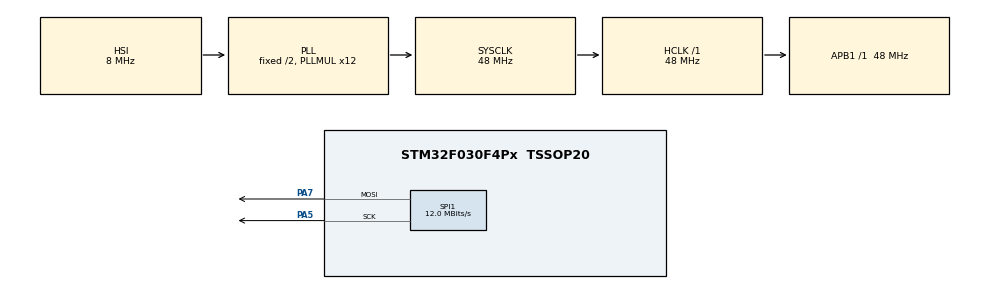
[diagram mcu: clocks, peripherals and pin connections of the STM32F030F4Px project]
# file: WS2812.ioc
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Mcu.Family=STM32F0
Mcu.Name=STM32F030F4Px
Mcu.Package=TSSOP20
NVIC.TIM17_IRQn=true\:0\:0\:false\:false\:true\:true\:true\:true
PA13.Mode=Serial_Wire
PA13.Signal=SYS_SWDIO
PA14.Mode=Serial_Wire
PA14.Signal=SYS_SWCLK
PA5.GPIO_PuPd=GPIO_PULLDOWN
PA5.Mode=TX_Only_Simplex_Unidirect_Master
PA5.Signal=SPI1_SCK
PA7.GPIO_PuPd=GPIO_PULLDOWN
PA7.Mode=TX_Only_Simplex_Unidirect_Master
PA7.Signal=SPI1_MOSI
PF0-OSC_IN.Mode=HSE-External-Oscillator
PF0-OSC_IN.Signal=RCC_OSC_IN
PF1-OSC_OUT.Mode=HSE-External-Oscillator
PF1-OSC_OUT.Signal=RCC_OSC_OUT
ProjectManager.HeapSize=0x200
ProjectManager.StackSize=0x400
ProjectManager.TargetToolchain=STM32CubeIDE
RCC.AHBFreq_Value=48000000
RCC.APB1Freq_Value=48000000
RCC.APB1TimFreq_Value=48000000
RCC.HCLKFreq_Value=48000000
RCC.PLLMUL=RCC_PLL_MUL12
RCC.SYSCLKFreq_VALUE=48000000
RCC.SYSCLKSource=RCC_SYSCLKSOURCE_PLLCLK
SPI1.BaudRatePrescaler=SPI_BAUDRATEPRESCALER_4
SPI1.CalculateBaudRate=12.0 MBits/s
SPI1.DataSize=SPI_DATASIZE_15BIT
SPI1.Direction=SPI_DIRECTION_2LINES
SPI1.Mode=SPI_MODE_MASTER
SPI1.NSSPMode=SPI_NSS_PULSE_DISABLE
SPI1.VirtualType=VM_MASTER
TIM17.AutoReloadPreload=TIM_AUTORELOAD_PRELOAD_ENABLE
TIM17.Prescaler=47999
TIM17.RepetitionCounter=10
VP_TIM17_VS_ClockSourceINT.Mode=Enable_Timer
board=custom

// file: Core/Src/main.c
/* USER CODE BEGIN Header */
/**
  ******************************************************************************
  * @file           : main.c
  * @brief          : Main program body
  ******************************************************************************
  * @attention
  *
  * Copyright (c) 2022 STMicroelectronics.
  * All rights reserved.
  *
  * This software is licensed under terms that can be found in the LICENSE file
  * in the root directory of this software component.
  * If no LICENSE file comes with this software, it is provided AS-IS.
  *
  ******************************************************************************
  */
/* USER CODE END Header */
#include "main.h"

/* USER CODE BEGIN Includes */
#include "stdlib.h"
/* USER CODE END Includes */

/* USER CODE BEGIN PD */
//#define HIGH_CODE (0x7FC0) /*111111111000000*/
//#define LOW_CODE (0x7C00)  /*111110000000000*/
#define HIGH_CODE (0x01FF) /*111111111000000*/
#define LOW_CODE (0x001F)  /*111110000000000*/
/* USER CODE END PD */

SPI_HandleTypeDef hspi1;

TIM_HandleTypeDef htim17;

/* USER CODE BEGIN PV */
uint16_t u16ValueLed[2] =
{
 LOW_CODE,
 HIGH_CODE,
};

uint32_t u32Delay = 1000;
uint32_t u32Colors[5] =
{
 0x0,
 0xFFD000,
 0xFFD000,
 0x00FF00,
 0x0000FF,
};

uint32_t u32ColorsMax[5] =
{
 0x0,
 0xFFD000,
 0xFFD000,
 0x00FF00,
 0x0000FF,
};

/* USER CODE END PV */

void SystemClock_Config(void);
static void MX_GPIO_Init(void);
static void MX_SPI1_Init(void);
static void MX_TIM17_Init(void);

/* USER CODE BEGIN 0 */

void WritePixel(uint8_t Red, uint8_t Green, uint8_t Blue);
void WritePixelColor(uint32_t Color);

void WritePixel(uint8_t Red, uint8_t Green, uint8_t Blue)
{
    uint8_t u8Temp;

    for(int i=0; i<8; i++)
    {
        u8Temp = Green & 0x80;
        Green <<= 1;
        u8Temp >>=7;
        SPI1->DR = u16ValueLed[u8Temp];
        while((SPI1->SR & SPI_SR_FTLVL) == SPI_SR_FTLVL);
    }

    for(int i=0; i<8; i++)
    {
        u8Temp = Red & 0x80;
        Red <<= 1;
        u8Temp >>=7;
        SPI1->DR = u16ValueLed[u8Temp];
        while((SPI1->SR & SPI_SR_FTLVL) == SPI_SR_FTLVL);
    }

    for(int i=0; i<8; i++)
    {
        u8Temp = Blue & 0x80;
        Blue <<= 1;
        u8Temp >>=7;
        SPI1->DR = u16ValueLed[u8Temp];
        while((SPI1->SR & SPI_SR_FTLVL) == SPI_SR_FTLVL);
    }
}

void WritePixelColor(uint32_t Color)
{
    uint8_t Green;
    uint8_t Red;
    uint8_t Blue;
    uint8_t u8Temp;

    Blue = Color & 0xFF;
    Color >>= 8;
    Green = Color & 0xFF;
    Color >>= 8;
    Red = Color & 0xFF;
    WritePixel(Red, Green, Blue);

}

/* USER CODE END 0 */

int main(void)
{
  /* USER CODE BEGIN 1 */
	uint32_t Red = 0;
	uint32_t Green = 0xFF;
	uint32_t Blue = 0;
	uint32_t RedDir = 0;
	uint32_t GreenDir = 0;
	uint32_t BlueDir = 0;
	uint32_t Color;
	uint32_t u32Count = 0;
	uint32_t u32Sub = 0;
	uint32_t u32Delay = 0;
	uint32_t u32Intensidad = 0;
  /* USER CODE END 1 */

  /* MCU Configuration--------------------------------------------------------*/

  /* Reset of all peripherals, Initializes the Flash interface and the Systick. */
  HAL_Init();

  /* Configure the system clock */
  SystemClock_Config();

  /* Initialize all configured peripherals */
  MX_GPIO_Init();
  MX_SPI1_Init();
  MX_TIM17_Init();
  /* USER CODE BEGIN 2 */
  SPI1->CR1 |= SPI_CR1_SPE;

  srand(SysTick->VAL);
  for(int i=0; i<60; i++)
  {
      WritePixelColor(0xFFFFFF);
  }
  HAL_Delay(2000);
  /* USER CODE END 2 */

  /* Infinite loop */
  while (1)
  {
	  u32Count++;
	  if((u32Count & 0x0F) == 0)
	  {
		  for(int i=0; i<60; i++)
		  {
			  WritePixelColor(0xFFDF00);
		  }
	      HAL_Delay(2000);
	  }
	  else if ((u32Count & 0x07) == 0)
	  {
		  Color = rand();
		  srand(SysTick->VAL + Color);
		  for(int i=0; i<60; i++)
		  {

			  Color = rand() >> (12 + 16);
			  Color %= 5;
			  Color = u32ColorsMax[Color];
			  WritePixelColor(Color);
		  }
	      HAL_Delay(2000);

	  }
	  else
	  {
		  u32Sub = rand() >> (30);
		  u32Sub &= 1;
		  u32Delay = rand();
		  srand(SysTick->VAL + u32Delay);
		  u32Delay = rand() >> (12 + 16);
		  u32Delay %= 1;
		  u32Delay += 1;
		  u32Delay *= 1000;
		  if(u32Sub & 1)
		  {
			  Color = rand();
			  srand(SysTick->VAL + Color);
			  for(int i=0; i<60; i++)
			  {
				  Color = rand() >> (12+ 16);
				  Color %= 5;
				  Color = u32Colors[Color];
				  u32Intensidad = rand() >> (10+ 16);
				  u32Intensidad %= 8;

					Red = Color >> 16;
					Red &= 0xFF;
					Red >>= u32Intensidad;
					Green = Color >> 8;
					Green &= 0xFF;
					Green >>= u32Intensidad;
					Blue = Color >> 0;
					Blue &= 0xFF;
					Blue >>= u32Intensidad;
					Color = Red << 16;
					Color |= Green << 8;
					Color |= Blue << 0;
				  WritePixelColor(Color);
			  }
		  }
		  else
		  {
			  for(int i=0; i<60; i++)
			  {
				  WritePixelColor(0);
			  }
		  }
	      HAL_Delay(u32Delay);
	  }
  }
}

void SystemClock_Config(void)
{
  RCC_OscInitTypeDef RCC_OscInitStruct = {0};
  RCC_ClkInitTypeDef RCC_ClkInitStruct = {0};

  /** Initializes the RCC Oscillators according to the specified parameters
  * in the RCC_OscInitTypeDef structure.
  */
  RCC_OscInitStruct.OscillatorType = RCC_OSCILLATORTYPE_HSI;
  RCC_OscInitStruct.HSIState = RCC_HSI_ON;
  RCC_OscInitStruct.HSICalibrationValue = RCC_HSICALIBRATION_DEFAULT;
  RCC_OscInitStruct.PLL.PLLState = RCC_PLL_ON;
  RCC_OscInitStruct.PLL.PLLSource = RCC_PLLSOURCE_HSI;
  RCC_OscInitStruct.PLL.PLLMUL = RCC_PLL_MUL12;
  RCC_OscInitStruct.PLL.PREDIV = RCC_PREDIV_DIV1;
  if (HAL_RCC_OscConfig(&RCC_OscInitStruct) != HAL_OK)
  {
    Error_Handler();
  }

  /** Initializes the CPU, AHB and APB buses clocks
  */
  RCC_ClkInitStruct.ClockType = RCC_CLOCKTYPE_HCLK|RCC_CLOCKTYPE_SYSCLK
                              |RCC_CLOCKTYPE_PCLK1;
  RCC_ClkInitStruct.SYSCLKSource = RCC_SYSCLKSOURCE_PLLCLK;
  RCC_ClkInitStruct.AHBCLKDivider = RCC_SYSCLK_DIV1;
  RCC_ClkInitStruct.APB1CLKDivider = RCC_HCLK_DIV1;

  if (HAL_RCC_ClockConfig(&RCC_ClkInitStruct, FLASH_LATENCY_1) != HAL_OK)
  {
    Error_Handler();
  }
}

static void MX_SPI1_Init(void)
{

  /* SPI1 parameter configuration*/
  hspi1.Instance = SPI1;
  hspi1.Init.Mode = SPI_MODE_MASTER;
  hspi1.Init.Direction = SPI_DIRECTION_2LINES;
  hspi1.Init.DataSize = SPI_DATASIZE_15BIT;
  hspi1.Init.CLKPolarity = SPI_POLARITY_LOW;
  hspi1.Init.CLKPhase = SPI_PHASE_1EDGE;
  hspi1.Init.NSS = SPI_NSS_SOFT;
  hspi1.Init.BaudRatePrescaler = SPI_BAUDRATEPRESCALER_4;
  hspi1.Init.FirstBit = SPI_FIRSTBIT_MSB;
  hspi1.Init.TIMode = SPI_TIMODE_DISABLE;
  hspi1.Init.CRCCalculation = SPI_CRCCALCULATION_DISABLE;
  hspi1.Init.CRCPolynomial = 7;
  hspi1.Init.CRCLength = SPI_CRC_LENGTH_DATASIZE;
  hspi1.Init.NSSPMode = SPI_NSS_PULSE_DISABLE;
  if (HAL_SPI_Init(&hspi1) != HAL_OK)
  {
    Error_Handler();
  }

}

static void MX_TIM17_Init(void)
{

  htim17.Instance = TIM17;
  htim17.Init.Prescaler = 47999;
  htim17.Init.CounterMode = TIM_COUNTERMODE_UP;
  htim17.Init.Period = 65535;
  htim17.Init.ClockDivision = TIM_CLOCKDIVISION_DIV1;
  htim17.Init.RepetitionCounter = 10;
  htim17.Init.AutoReloadPreload = TIM_AUTORELOAD_PRELOAD_ENABLE;
  if (HAL_TIM_Base_Init(&htim17) != HAL_OK)
  {
    Error_Handler();
  }

}

static void MX_GPIO_Init(void)
{

  /* GPIO Ports Clock Enable */
  __HAL_RCC_GPIOF_CLK_ENABLE();
  __HAL_RCC_GPIOA_CLK_ENABLE();

}

void Error_Handler(void)
{
  __disable_irq();
  while (1)
  {
  }
}
